AUTOSAR XML (schema 4-2-2)
package /ComponentTypes
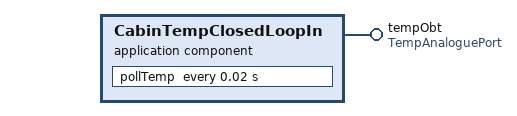
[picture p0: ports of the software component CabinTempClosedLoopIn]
  application sw component type CabinTempClosedLoopIn
    provide port tempObt: provided-com-specs=[{data-element=tempIn, init-value=0}, {data-element=tempOut, init-value=0}], provided-interface=TempAnaloguePort
    behavior CabinTempClosedLoopIn_InternalBehavior: data-type-mapping=tempMapSet
      timing event TMT_run: start-on-event=pollTemp, period=0.02
      runnable pollTemp
        data-send-points:
          access SEND_tempObt_tempIn: accessed-variable=tempObt.tempIn
          access SEND_tempObt_tempOut: accessed-variable=tempObt.tempOut
  swc implementation CabinTempClosedLoopIn_Implementation: behavior=CabinTempClosedLoopIn_InternalBehavior
